# STM32WL3xx register map
File version: 1.0
Registers are 32-bit, read-write, reset 0x0 unless marked. A register's access mark holds for its fields unless they carry their own. Offsets are from the block's base; [hi:lo] are bit positions; {n}, {i} and the like mark numbered series.

## I2C1 — Inter-integrated circuit (I2C)
Base 0x41000000
Same registers: I2C2 0x41001000
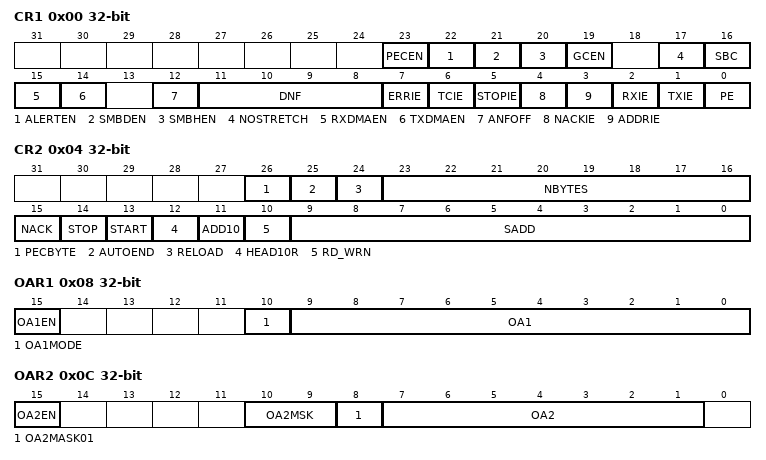
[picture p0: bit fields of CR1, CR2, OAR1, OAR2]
0x00 CR1 — (@ 0x00000000) Control register 1
  [23] PECEN, [22] ALERTEN, [21] SMBDEN, [20] SMBHEN, [19] GCEN, [17] NOSTRETCH, [16] SBC, [15] RXDMAEN, [14] TXDMAEN, [12] ANFOFF, [11:8] DNF, [7] ERRIE, [6] TCIE, [5] STOPIE, [4] NACKIE, [3] ADDRIE, [2] RXIE, [1] TXIE, [0] PE
0x04 CR2 — (@ 0x00000004) Control register 2
  [26] PECBYTE
  [25] AUTOEND
  [24] RELOAD
  [23:16] NBYTES
  [15] NACK
    0=ACK (ACK is sent after current received byte.); 1=NACK (NACK is sent after current received byte.)
  [14] STOP
  [13] START
  [12] HEAD10R
  [11] ADD10
    0=MODE_7BIT (Master operates in 7-bit addressing mode.); 1=MODE_10BIT (Master operates in 10-bit addressing mode.)
  [10] RD_WRN
    0=WRITE (Master request a write transfer.); 1=READ (Master request a read transfer.)
  [9:0] SADD
0x08 OAR1 — (@ 0x00000008) Own address register 1
  [15] OA1EN, [10] OA1MODE, [9:0] OA1
0x0C OAR2 — (@ 0x0000000C) Own address register 2
  [15] OA2EN
  [10:9] OA2MSK
  [8] OA2MASK01 — OA2[1] is masked, Only OA2[7:2] are compared
  [7:1] OA2
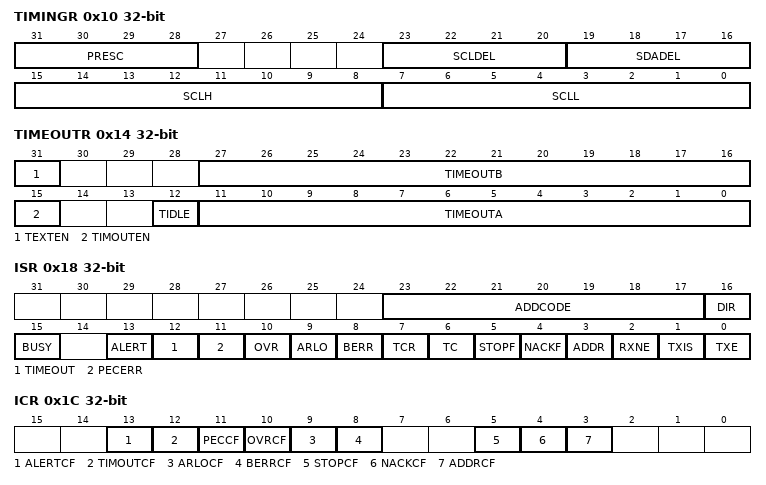
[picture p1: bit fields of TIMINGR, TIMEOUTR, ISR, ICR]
0x10 TIMINGR — (@ 0x00000010) Timing register
  [31:28] PRESC, [23:20] SCLDEL, [19:16] SDADEL, [15:8] SCLH, [7:0] SCLL
0x14 TIMEOUTR — (@ 0x00000014) Timeout register
  [31] TEXTEN
  [27:16] TIMEOUTB
  [15] TIMOUTEN
  [12] TIDLE
    0=SCL_LOW; 1=SDA_SCL_HIGH
  [11:0] TIMEOUTA
0x18 ISR — (@ 0x00000018) Interrupt and Status register
  [23:17] ADDCODE
  [16] DIR
    0=WRITE; 1=READ
  [15] BUSY
  [13] ALERT
  [12] TIMEOUT
  [11] PECERR
  [10] OVR
  [9] ARLO
  [8] BERR
  [7] TCR
  [6] TC
  [5] STOPF
  [4] NACKF
  [3] ADDR
  [2] RXNE
  [1] TXIS
  [0] TXE
0x1C ICR — (@ 0x0000001C) Interrupt clear register
  [13] ALERTCF, [12] TIMOUTCF, [11] PECCF, [10] OVRCF, [9] ARLOCF, [8] BERRCF, [5] STOPCF, [4] NACKCF, [3] ADDRCF
0x20 PECR — (@ 0x00000020) PEC register
  [7:0] PEC
0x24 RXDR — (@ 0x00000024) Receive data register
  [7:0] RXDATA
0x28 TXDR — (@ 0x00000028) Transmit data register
  [7:0] TXDATA

## SPI1 — Serial peripheral interface/Inter-IC sound (SPI)
Base 0x41002000
Same registers: SPI3 0x41007000
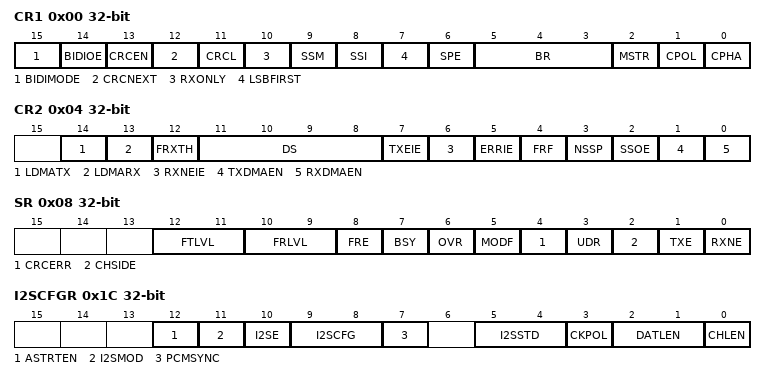
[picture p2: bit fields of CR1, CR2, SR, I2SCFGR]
0x00 CR1 — (@ 0x00000000) Control register 1
  [15] BIDIMODE
  [14] BIDIOE
  [13] CRCEN
  [12] CRCNEXT
  [11] CRCL
    0=CRC_8BIT (8-bit CRC length); 1=CRC_16BIT (16-bit CRC length)
  [10] RXONLY
  [9] SSM
  [8] SSI
  [7] LSBFIRST
    1=LSB_FIRST (Data is transmitted/received with the LSB first); 0=MSB_FIRST (Data is transmitted/received with the MSB first)
  [6] SPE
  [5:3] BR
    0=DIV2 (BaudRate control equal to fPCLK/2); 1=DIV4 (BaudRate control equal to fPCLK/4); 2=DIV8 (BaudRate control equal to fPCLK/8); 3=DIV16 (BaudRate control equal to fPCLK/16); 4=DIV32 (BaudRate control equal to fPCLK/32); 5=DIV64 (BaudRate control equal to fPCLK/64); 6=DIV128 (BaudRate control equal to fPCLK/128); 7=DIV256 (BaudRate control equal to fPCLK/256)
  [2] MSTR
  [1] CPOL
    0=LOW (Clock to 0 when idle); 1=HIGH (Clock to 1 when idle)
  [0] CPHA
    0=PHASE_1EDGE (First clock transition is the first data capture edge); 1=PHASE_2EDGE (Second clock transition is the first data capture edge)
0x04 CR2 — (@ 0x00000004) Control register 2
  [14] LDMATX
  [13] LDMARX
  [12] FRXTH
    0=HALF (RXNE event is generated if FIFO level is greater than or equal to 1/2 (16-bit)); 1=QUARTER (RXNE event is generated if FIFO level is greater than or equal to 1/4 (8-bit))
  [11:8] DS
    {v}=DATAWIDTH_{v+1}BIT (Data length for SPI transfer: {v+1} bits) (v=3..15)
  [7] TXEIE
  [6] RXNEIE
  [5] ERRIE
  [4] FRF
    0=MOTOROLA (Motorola mode. Used as default value); 1=TI (TI mode)
  [3] NSSP
  [2] SSOE
  [1] TXDMAEN
  [0] RXDMAEN
0x08 SR — (@ 0x00000008) Status register
  [12:11] FTLVL
    0=EMPTY (FIFO transmission empty); 1=QUARTER_FULL (FIFO transmission 1/4); 2=HALF_FULL (FIFO transmission 1/2); 3=FULL (FIFO transmission full)
  [10:9] FRLVL
    0=EMPTY (FIFO reception empty); 1=QUARTER_FULL (FIFO reception 1/4); 2=HALF_FULL (FIFO reception 1/2); 3=FULL (FIFO reception full)
  [8] FRE
  [7] BSY
  [6] OVR
  [5] MODF
  [4] CRCERR
  [3] UDR
  [2] CHSIDE
  [1] TXE
  [0] RXNE
0x0C DR — (@ 0x0000000C) Data register
  [15:0] DR
0x10 CRCPR — (@ 0x00000010) CRC polynomial register
  [15:0] CRCPOLY
0x14 RXCRCR — (@ 0x00000014) RX CRC register
  [15:0] RXCRC
0x18 TXCRCR — (@ 0x00000018) TX CRC register
  [15:0] TXCRC
0x1C I2SCFGR — (@ 0x0000001C) I2S configuration register
  [12] ASTRTEN
  [11] I2SMOD
  [10] I2SE
  [9:8] I2SCFG
    0=SLAVE_TX (Slave Tx configuration); 1=SLAVE_RX (Slave Rx configuration); 2=MASTER_TX (Master Tx configuration); 3=MASTER_RX (Master Rx configuration)
  [7] PCMSYNC
  [5:4] I2SSTD
  [3] CKPOL
    0=LOW (Clock steady state is low level); 1=HIGH (Clock steady state is high level)
  [2:1] DATLEN
  [0] CHLEN
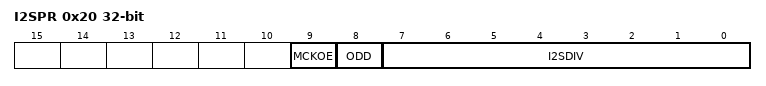
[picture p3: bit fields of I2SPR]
0x20 I2SPR — (@ 0x00000020) I2S prescaler register
  [9] MCKOE, [8] ODD, [7:0] I2SDIV
